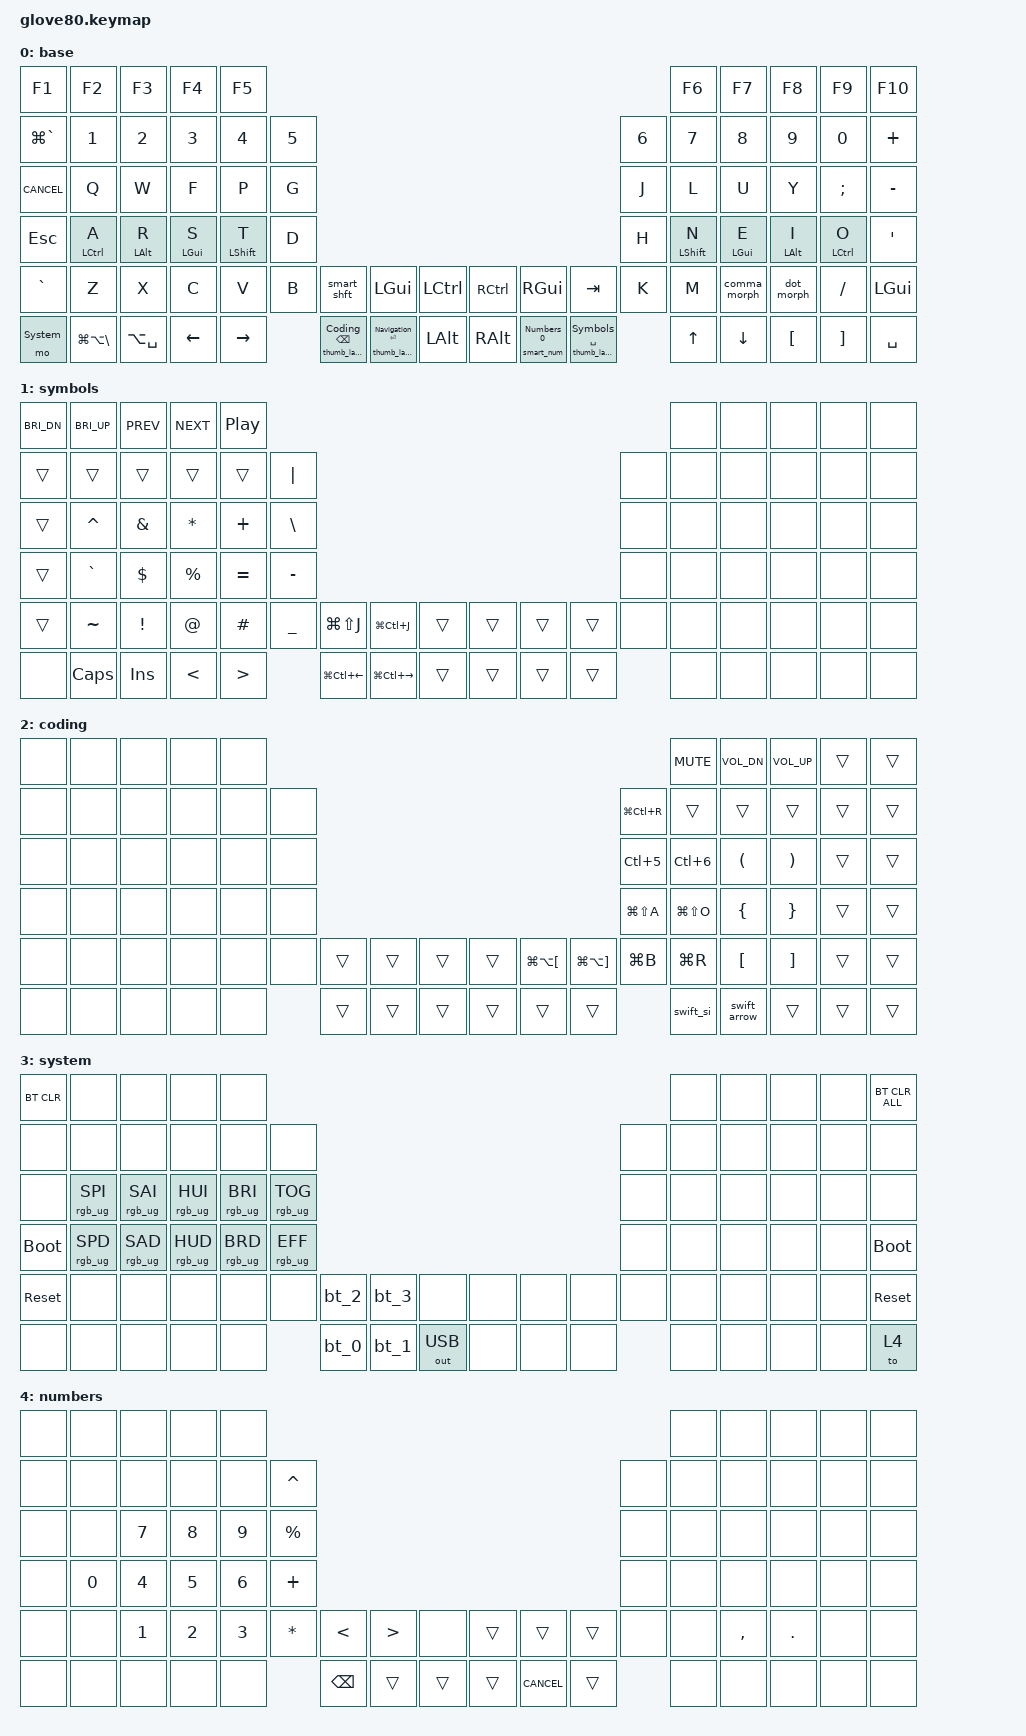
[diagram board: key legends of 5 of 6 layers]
/*
 * Copyright (c) 2020 The ZMK Contributors
 *
 * SPDX-License-Identifier: MIT
 */

#include <behaviors.dtsi>
#include <dt-bindings/zmk/keys.h>
#include <dt-bindings/zmk/bt.h>
#include <dt-bindings/zmk/ext_power.h>
#include <dt-bindings/zmk/outputs.h>
#include <dt-bindings/zmk/rgb.h>

#include "zmk-helpers/helper.h"
#include "zmk-helpers/key-labels/glove80.h"

#define HYPER LC(LS(LG(LALT)))

// MARK: Layer definitions

#define Base 0
#define Symbols 1
#define Coding 2
#define System 3
#define Numbers 4
#define Navigation 5

#include "combos.dtsi" // Requires layer aliasses
#include "mouse.dtsi"

/* To deal with the situation where there is no Lower layer, to keep &lower happy */
#ifndef LAYER_Lower
#define LAYER_Lower 0
#endif

// misc aliases
#define CANCEL      &kp K_CANCEL             // cancel caps-word, num-word and smart-mouse
#define DSK_MGR     &kp LG(GRAVE)            // desktop manager

// MARK: Nav cluster

// long-tap action on hold, short-tap action on all interrupts
#define MT_CORE \
    flavor = "tap-preferred"; \
    tapping-term-ms = <220>; \
    quick-tap-ms = <220>; \
    hold-trigger-key-positions = <0>;

&mt { MT_CORE };
ZMK_BEHAVIOR(mt_home, hold_tap, bindings = <&masked_home>, <&kp>; MT_CORE)
ZMK_BEHAVIOR(mt_end,  hold_tap,  bindings = <&masked_end>, <&kp>; MT_CORE)

#define NAV_LEFT  &mt_home 0   LEFT    // tap: left  | long-tap: beginning of line
#define NAV_RIGHT &mt_end 0    RIGHT   // tap: right | long-tap: end       of line
#define NAV_UP    &mt LG(UP)   UP      // tap: up    | long-tap: beginning of document
#define NAV_DOWN  &mt LG(DOWN) DOWN09    // tap: down  | long-tap: end       of document
#define NAV_BSPC  &mt LG(BSPC) BSPC    // tap: bspc  | long-tap: delete word backward
#define NAV_DEL   &mt LG(DEL)  DEL     // tap: del   | long-tap: delete word forward

// mask CTRL when holding left/right to avoid accidental jumps to beginning/end of document
#define MASK_MODS(NAME, MODS, BINDING) \
    ZMK_BEHAVIOR(NAME, mod_morph, \
        bindings = <BINDING>, <BINDING>; \
        mods = <MODS>; \
    )
MASK_MODS(masked_home, (MOD_LCTL), &kp HOME)
MASK_MODS(masked_end,  (MOD_LCTL), &kp END)

// MARK: Global settings

#define QUICK_TAP_MS 175

&sk {  // sticky-key config
    release-after-ms = <900>;  // release after 0.6s
    quick-release;             // no double capitalization when rolling keys
};

&sl {  // sticky-layer config
    ignore-modifiers;          // allow chording sticky mods & layers
};

&lt {  // layer-tap config
    flavor = "balanced";
    tapping-term-ms = <200>;
    quick-tap-ms = <QUICK_TAP_MS>;
};

// MARK: Behaviors

// reuse basic mod-morph scheme
#define SIMPLE_MORPH(NAME, MOD, BINDING1, BINDING2) \
    ZMK_BEHAVIOR(NAME, mod_morph, \
        mods = <(MOD_L ## MOD|MOD_R ## MOD)>; \
        bindings = <BINDING1>, <BINDING2>; \
    )

// tap: left/right parenthesis | shft + tap: less-than/greater-than
SIMPLE_MORPH(lpar_lt, SFT, &kp LPAR, &kp LT)
SIMPLE_MORPH(rpar_gt, SFT, &kp RPAR, &kp GT)

// tap: comma | shift + tap: semicolon | ctrl + shift + tap: <
SIMPLE_MORPH(comma_morph, SFT, &kp COMMA, &comma_inner_morph)
SIMPLE_MORPH(comma_inner_morph, GUI, &kp SEMICOLON, &kp LESS_THAN)

// tap: dot | shift + tap: colon | ctrl + shift + tap: >
SIMPLE_MORPH(dot_morph, SFT, &kp DOT, &dot_inner_morph)
SIMPLE_MORPH(dot_inner_morph, GUI, &kp COLON, &kp GREATER_THAN)

// Homerow mods

#define KEYS_L LT0 LT1 LT2 LT3 LT4 LT5 LM0 LM1 LM2 LM3 LM4 LM5 LB0 LB1 LB2 LB3 LB4 LB5 LN0 LN1 LN2 LN3 LN4 LN5  // left hand
#define KEYS_R RT0 RT1 RT2 RT3 RT4 RT5 RM0 RM1 RM2 RM3 RM4 RM5 RB0 RB1 RB2 RB3 RB4 RB5 RN0 RN1 RN2 RN3 RN4 RN5  // right hand
#define THUMBS LH0 LH1 LH2 LH3 LH4 LH5 LH1 RH0 RH1 RH2 RH3 RH3 RH4 RH5                                          // thumbs

#define MAKE_HRM(NAME, HOLD, TAP, TRIGGER_POS) \
    ZMK_BEHAVIOR(NAME, hold_tap, \
        flavor = "balanced"; \
        tapping-term-ms = <280>; \
        quick-tap-ms = <QUICK_TAP_MS>; \
        require-prior-idle-ms = <150>; \
        bindings = <HOLD>, <TAP>; \
        hold-trigger-key-positions = <TRIGGER_POS>; \
        hold-trigger-on-release; \
    )
MAKE_HRM(hml, &kp, &kp, KEYS_R THUMBS)  // left-hand HRMs
MAKE_HRM(hmr, &kp, &kp, KEYS_L THUMBS)  // right-hand HRMs

MAKE_HRM(hml_repeat, &kp, &key_repeat, KEYS_R THUMBS)  // used for HRM-combo
MAKE_HRM(hmr_lpar_lt, &kp, &lpar_lt, KEYS_L THUMBS)    // "    "   "   "
MAKE_HRM(hmr_rpar_gt, &kp, &rpar_gt, KEYS_L THUMBS)    // "    "   "   "

ZMK_BEHAVIOR(thumb_layer, hold_tap,
    flavor = "balanced";
    tapping-term-ms = <200>;
    quick-tap-ms = <300>;
    bindings = <&mo>, <&kp>;
)

// Glove80 specific behaviors, they don't work with Urob's ZMK fork
// ZMK_BEHAVIOR(rgb_ug_status_macro, macro,
//     bindings = <&rgb_ug RGB_STATUS>;
// )

// ZMK_BEHAVIOR(magic, hold_tap,
//     flavor = "tap-preferred";
//     tapping-term-ms = <200>;
//     bindings = <&mo>, <&rgb_ug_status_macro>;
// )

ZMK_BEHAVIOR(bt_0, macro,
    bindings
        = <&out OUT_BLE>,
          <&bt BT_SEL 0>;
)

ZMK_BEHAVIOR(bt_1, macro,
    bindings
        = <&out OUT_BLE>,
          <&bt BT_SEL 1>;
)

ZMK_BEHAVIOR(bt_2, macro,
    bindings
        = <&out OUT_BLE>,
          <&bt BT_SEL 2>;
)

ZMK_BEHAVIOR(bt_3, macro,
    bindings
        = <&out OUT_BLE>,
          <&bt BT_SEL 3>;
)

// Caps-word and num-word

// tap: sticky-shift | shift + tap/ double-tap: caps-word | hold: shift
ZMK_BEHAVIOR(smart_shft, mod_morph,
    bindings = <&sk LSHFT>, <&caps_word>;
    mods = <(MOD_LSFT)>;
)

&caps_word {  // mods deactivate caps-word, requires PR #1451
    /delete-property/ ignore-modifiers;
    continue-list = <UNDERSCORE MINUS PLUS DOT BSPC DEL COMMA FSLH>;
};

// tap: num-word | double-tap: sticky num-layer | hold: num-layer
#define SMART_NUM &smart_num Numbers 0
ZMK_BEHAVIOR(smart_num, hold_tap,
    flavor = "balanced";
    tapping-term-ms = <200>;
    quick-tap-ms = <QUICK_TAP_MS>;
    bindings = <&mo>, <&num_dance>;
)

ZMK_BEHAVIOR(num_dance, tap_dance,
    tapping-term-ms = <200>;
    bindings = <&num_word>, <&sl Numbers>;  // reverse this for sticky-num on single tap
)

&num_word {  // num-word, requires PR #1451
    layers = <Numbers>;
    continue-list = <BSPC DEL DOT COMMA PLUS MINUS STAR FSLH EQUAL>;
};

// Alt+Tab swapper, requires PR #1366
ZMK_BEHAVIOR(swapper, tri_state,
    bindings = <&kt LCMD>, <&kp TAB>, <&kt LCMD>;
    ignored-key-positions = <LT5 LH5 RH5 LF1 LF2 RF1 RF2 LH2 RT1>; // Tab, Shift, Arrow key positions and DEL/BSPC to quit app/close window from altTab
)

//////////////////////////////////////////////////////////////////////////
//
// Approximation of Pascal Getreuer's Select Word macro from QMK
// - https://getreuer.info/posts/keyboards/select-word/index.html
//
//////////////////////////////////////////////////////////////////////////

// SELECT_WORD_DELAY defines how long the macro waits (milliseconds)
// after moving the cursor before it selects a word.  A larger delay
// may allow the macro to move to the next word upon each invocation.
#define SELECT_WORD_DELAY 1

ZMK_BEHAVIOR(select_none, macro,
    wait-ms = <SELECT_WORD_DELAY>;
    tap-ms = <SELECT_WORD_DELAY>;
    bindings = <&kp DOWN &kp UP &kp RIGHT &kp LEFT>;
)

// select a word (jumps to next word upon each successive invocation)
ZMK_BEHAVIOR(select_word, mod_morph,
    bindings = <&select_word_right>, <&select_word_left>;
    mods = <(MOD_LSFT|MOD_RSFT)>;
)
ZMK_BEHAVIOR(select_word_right, macro,
    wait-ms = <SELECT_WORD_DELAY>;
    tap-ms = <SELECT_WORD_DELAY>;
    bindings = <&kp LA(RIGHT) &kp LA(LEFT) &kp LA(LS(RIGHT))>;
)
ZMK_BEHAVIOR(select_word_left, macro,
    wait-ms = <SELECT_WORD_DELAY>;
    tap-ms = <SELECT_WORD_DELAY>;
    bindings = <&kp LA(LEFT) &kp LA(RIGHT) &kp LA(LS(LEFT))>;
)

// extend current selection by one word
ZMK_BEHAVIOR(extend_word, mod_morph,
    bindings = <&extend_word_right>, <&extend_word_left>;
    mods = <(MOD_LSFT|MOD_RSFT)>;
)
ZMK_BEHAVIOR(extend_word_right, macro,
    wait-ms = <SELECT_WORD_DELAY>;
    tap-ms = <SELECT_WORD_DELAY>;
    bindings = <&kp LA(LS(RIGHT))>;
)
ZMK_BEHAVIOR(extend_word_left, macro,
    wait-ms = <SELECT_WORD_DELAY>;
    tap-ms = <SELECT_WORD_DELAY>;
    bindings = <&kp LA(LS(LEFT))>;
)

// select current line
ZMK_BEHAVIOR(select_line, mod_morph,
    bindings = <&select_line_right>, <&select_line_left>;
    mods = <(MOD_LSFT|MOD_RSFT)>;
)
ZMK_BEHAVIOR(select_line_right, macro,
    wait-ms = <SELECT_WORD_DELAY>;
    tap-ms = <SELECT_WORD_DELAY>;
    bindings = <&kp LG(LEFT) &kp LS(LG(RIGHT))>;
)
ZMK_BEHAVIOR(select_line_left, macro,
    wait-ms = <SELECT_WORD_DELAY>;
    tap-ms = <SELECT_WORD_DELAY>;
    bindings = <&kp LG(RIGHT) &kp LS(LG(LEFT))>;
)

// extend current selection by one line
ZMK_BEHAVIOR(extend_line, mod_morph,
    bindings = <&extend_line_right>, <&extend_line_left>;
    mods = <(MOD_LSFT|MOD_RSFT)>;
)
ZMK_BEHAVIOR(extend_line_right, macro,
    wait-ms = <SELECT_WORD_DELAY>;
    tap-ms = <SELECT_WORD_DELAY>;
    bindings = <&kp LS(DOWN) &kp LS(LG(RIGHT))>;
)
ZMK_BEHAVIOR(extend_line_left, macro,
    wait-ms = <SELECT_WORD_DELAY>;
    tap-ms = <SELECT_WORD_DELAY>;
    bindings = <&kp LS(UP) &kp LS(LG(LEFT))>;
)

// Swift string interpolation
ZMK_BEHAVIOR(swift_si, macro,
    wait-ms = <100>;
    tap-ms = <5>;
    bindings = <&kp BSLH &kp LPAR &kp RPAR>;
)

ZMK_BEHAVIOR(swift_arrow, macro,
    wait-ms = <100>;
    tap-ms = <5>;
    bindings = <&kp MINUS &kp GT>;
)

// MARK: Layers

ZMK_LAYER(base,
    &kp F1      &kp F2            &kp F3         &kp F4         &kp F5                                                                                                                                                &kp F6        &kp F7        &kp F8       &kp F9        &kp F10
    DSK_MGR     &kp N1            &kp N2         &kp N3         &kp N4        &kp N5                                                                                                                         &kp N6   &kp N7        &kp N8        &kp N9       &kp N0        &kp PLUS
    CANCEL      &kp Q             &kp W          &kp F          &kp P         &kp G                                                                                                                          &kp J    &kp L         &kp U         &kp Y        &kp SEMI      &kp MINUS
    &kp ESC     &hml LCTRL A      &hml LALT R    &hml LGUI S    &hml LSHFT T  &kp D                                                                                                                          &kp H    &hmr LSHFT N  &hmr LGUI E   &hmr LALT I  &hmr LCTRL O  &kp SQT
    &kp GRAVE   &kp Z             &kp X          &kp C          &kp V         &kp B   &smart_shft               &kp LGUI                       &kp LCTRL  &kp RCTRL  &kp RGUI    &kp TAB                     &kp K    &kp M         &comma_morph  &dot_morph   &kp FSLH      &kp LGUI
    &mo System  &kp LG(LA(BSLH))  &kp LA(SPACE)  &kp LEFT       &kp RIGHT             &thumb_layer Coding BSPC  &thumb_layer Navigation ENTER  &kp LALT   &kp RALT   SMART_NUM   &thumb_layer Symbols SPACE           &kp UP        &kp DOWN      &kp LBKT     &kp RBKT      &kp SPACE
)

ZMK_LAYER(symbols,
    &kp C_BRI_DN  &kp C_BRI_UP  &kp C_PREV  &kp C_NEXT  &kp C_PP                                                                                             &none  &none  &none  &none  &none
    &trans        &trans        &trans      &trans      &trans     &kp PIPE                                                                           &none  &none  &none  &none  &none  &none
    &trans        &kp CARET     &kp AMPS    &kp STAR    &kp PLUS   &kp BSLH                                                                           &none  &none  &none  &none  &none  &none
    &trans        &kp GRAVE     &kp DLLR    &kp PRCNT   &kp EQUAL  &kp MINUS                                                                          &none  &none  &none  &none  &none  &none
    &trans        &kp TILDE     &kp EXCL    &kp AT      &kp HASH   &kp UNDER  &kp LG(LS(J))      &kp LG(LC(J))      &trans  &trans  &trans  &trans    &none  &none  &none  &none  &none  &none
    &none         &kp CAPS      &kp INS     &kp LT      &kp GT                &kp LG(LC(LEFT))   &kp LG(LC(RIGHT))  &trans  &trans  &trans  &trans           &none  &none  &none  &none  &none
)

ZMK_LAYER(coding,
    &none  &none  &none  &none  &none                                                                                              &kp C_MUTE     &kp C_VOL_DN  &kp C_VOL_UP  &trans  &trans
    &none  &none  &none  &none  &none  &none                                                                        &kp LG(LC(R))  &trans         &trans        &trans        &trans  &trans
    &none  &none  &none  &none  &none  &none                                                                        &kp LC(N5)     &kp LC(N6)     &kp LPAR      &kp RPAR      &trans  &trans
    &none  &none  &none  &none  &none  &none                                                                        &kp LG(LS(A))  &kp LG(LS(O))  &kp LBRC      &kp RBRC      &trans  &trans
    &none  &none  &none  &none  &none  &none  &trans  &trans  &trans  &trans  &kp LG(LA(LBKT))  &kp LG(LA(RBKT))    &kp LG(B)      &kp LG(R)      &kp LBKT      &kp RBKT      &trans  &trans
    &none  &none  &none  &none  &none         &trans  &trans  &trans  &trans  &trans            &trans                             &swift_si      &swift_arrow  &trans        &trans  &trans
)

ZMK_LAYER(system,
    &bt BT_CLR    &none            &none            &none            &none                                                                                           &none   &none   &none   &none  &bt BT_CLR_ALL
    &none         &none            &none            &none            &none            &none                                                                  &none   &none   &none   &none   &none  &none
    &none         &rgb_ug RGB_SPI  &rgb_ug RGB_SAI  &rgb_ug RGB_HUI  &rgb_ug RGB_BRI  &rgb_ug RGB_TOG                                                        &none   &none   &none   &none   &none  &none
    &bootloader   &rgb_ug RGB_SPD  &rgb_ug RGB_SAD  &rgb_ug RGB_HUD  &rgb_ug RGB_BRD  &rgb_ug RGB_EFF                                                        &none   &none   &none   &none   &none  &bootloader
    &sys_reset    &none            &none            &none            &none            &none            &bt_2   &bt_3         &none   &none   &none   &none   &none   &none   &none   &none   &none  &sys_reset
    &none         &none            &none            &none            &none                             &bt_0   &bt_1  &out OUT_USB   &none   &none   &none           &none   &none   &none   &none  &to 4
)

ZMK_LAYER(numbers,
    &none   &none   &none   &none   &none                                                                          &none   &none      &none    &none  &none
    &none   &none   &none   &none   &none   &kp CARET                                                       &none  &none   &none      &none    &none  &none
    &none   &none   &kp N7  &kp N8  &kp N9  &kp PRCNT                                                       &none  &none   &none      &none    &none  &none
    &none   &kp N0  &kp N4  &kp N5  &kp N6  &kp PLUS                                                        &none  &none   &none      &none    &none  &none
    &none   &none   &kp N1  &kp N2  &kp N3  &kp STAR    &kp LT   &kp GT  &none  &trans  &trans   &trans     &none  &none   &kp COMMA  &kp DOT  &none  &none
    &none   &none   &none   &none   &none               &kp BSPC &trans  &trans &trans  CANCEL   &trans            &none   &none      &none    &none  &none
)

ZMK_LAYER(navigation,
    &none   &none   &none   &none  &none                                                                  &none         &none         &none     &none    &none
    &none   &none   &none   &none  &none  &none                                             &none         &none         &none         &none     &none    &none
    &none   &none   &none   &none  &none  &none                                             &none         &kp LS(TAB)   &swapper      &none     &none    &none
    &none   &none   &none   &none  &none  &none                                             &select_none  &extend_line  &extend_word  U_WH_U    U_WH_L   &none
    &none   &none   &none   &none  &none  &none   &none  &none  &none  &none  &none  &none  &kp LG(A)     &select_line  &select_word  U_WH_D    U_WH_R   &none
    &none   &none   &none   &none  &none          &none  &none  &none  &none  &none  &none                &kp PG_UP     &kp PG_DN     &kp HOME  &kp END  &none
)

// MARK: Layer Template

// ZMK_LAYER(empty,
//     &none   &none   &none   &none   &none                                                            &none   &none  &none  &none  &none
//     &none   &none   &none   &none   &none   &none                                             &none  &none   &none  &none  &none  &none
//     &none   &none   &none   &none   &none   &none                                             &none  &none   &none  &none  &none  &none
//     &none   &none   &none   &none   &none   &none                                             &none  &none   &none  &none  &none  &none
//     &none   &none   &none   &none   &none   &none   &none  &none  &none  &none  &none  &none  &none  &none   &none  &none  &none  &none
//     &none   &none   &none   &none   &none           &none  &none  &none  &none  &none  &none         &none  &none   &none  &none  &none
// )
